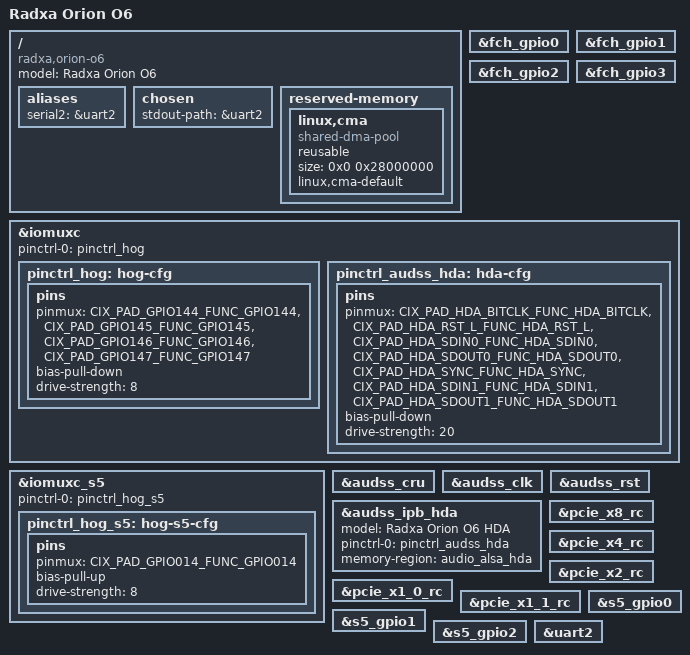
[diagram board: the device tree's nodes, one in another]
// SPDX-License-Identifier: BSD-3-Clause
/*
 * Copyright 2025 Cix Technology Group Co., Ltd.
 *
 */

/dts-v1/;

#include "sky1.dtsi"
#include "sky1-pinfunc.h"

/ {
	model = "Radxa Orion O6";
	compatible = "radxa,orion-o6", "cix,sky1";

	aliases {
		serial2 = &uart2;
	};

	chosen {
		stdout-path = &uart2;
	};

	reserved-memory {
		#address-cells = <2>;
		#size-cells = <2>;
		ranges;

		linux,cma {
			compatible = "shared-dma-pool";
			reusable;
			size = <0x0 0x28000000>;
			linux,cma-default;
		};
	};

};

&fch_gpio0 {
	status = "okay";
};

&fch_gpio1 {
	status = "okay";
};

&fch_gpio2 {
	status = "okay";
};

&fch_gpio3 {
	status = "okay";
};

&iomuxc {
	pinctrl-names = "default";
	pinctrl-0 = <&pinctrl_hog>;

	pinctrl_hog: hog-cfg {
		pins {
			pinmux = <CIX_PAD_GPIO144_FUNC_GPIO144>,
				<CIX_PAD_GPIO145_FUNC_GPIO145>,
				<CIX_PAD_GPIO146_FUNC_GPIO146>,
				<CIX_PAD_GPIO147_FUNC_GPIO147>;
			bias-pull-down;
			drive-strength = <8>;
		};
	};

	pinctrl_audss_hda: hda-cfg {
		pins {
			pinmux = <CIX_PAD_HDA_BITCLK_FUNC_HDA_BITCLK>,
			       <CIX_PAD_HDA_RST_L_FUNC_HDA_RST_L>,
			       <CIX_PAD_HDA_SDIN0_FUNC_HDA_SDIN0>,
			       <CIX_PAD_HDA_SDOUT0_FUNC_HDA_SDOUT0>,
			       <CIX_PAD_HDA_SYNC_FUNC_HDA_SYNC>,
			       <CIX_PAD_HDA_SDIN1_FUNC_HDA_SDIN1>,
			       <CIX_PAD_HDA_SDOUT1_FUNC_HDA_SDOUT1>;
			bias-pull-down;
			drive-strength = <20>;
		};
	};
};

&iomuxc_s5 {
	pinctrl-names = "default";
	pinctrl-0 = <&pinctrl_hog_s5>;

	pinctrl_hog_s5: hog-s5-cfg {
		pins {
			pinmux = <CIX_PAD_GPIO014_FUNC_GPIO014>;
			bias-pull-up;
			drive-strength = <8>;

		};
	};
};

&audss_cru {
	status = "okay";
};

&audss_clk {
	status = "okay";
};

&audss_rst {
	status = "okay";
};

&audss_ipb_hda {
	model = "Radxa Orion O6 HDA";
	pinctrl-names = "default";
	pinctrl-0 = <&pinctrl_audss_hda>;
	memory-region = <&audio_alsa_hda>;
	status = "okay";
};

&pcie_x8_rc {
	status = "okay";
};

&pcie_x4_rc {
	status = "okay";
};

&pcie_x2_rc {
	status = "okay";
};

&pcie_x1_0_rc {
	status = "okay";
};

&pcie_x1_1_rc {
	status = "okay";
};

&s5_gpio0 {
	status = "okay";
};

&s5_gpio1 {
	status = "okay";
};

&s5_gpio2 {
	status = "okay";
};

&uart2 {
	status = "okay";
};
